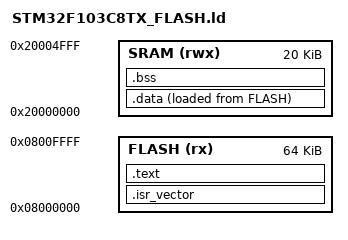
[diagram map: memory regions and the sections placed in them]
/* STM32F103C8T6 — 64 KB Flash, 20 KB SRAM */
ENTRY(Reset_Handler)

MEMORY
{
    FLASH (rx)  : ORIGIN = 0x08000000, LENGTH = 64K
    SRAM  (rwx) : ORIGIN = 0x20000000, LENGTH = 20K
}

SECTIONS
{
    .isr_vector :
    {
        KEEP(*(.isr_vector))
    } > FLASH

    .text :
    {
        *(.text*)
        *(.rodata*)
        KEEP(*(.init))
        KEEP(*(.fini))
    } > FLASH

    _sidata = LOADADDR(.data);

    .data :
    {
        _sdata = .;
        *(.data*)
        _edata = .;
    } > SRAM AT > FLASH

    .bss :
    {
        _sbss = .;
        *(.bss*)
        *(COMMON)
        _ebss = .;
    } > SRAM

    _estack = ORIGIN(SRAM) + LENGTH(SRAM);
}
